AUTOSAR XML (schema 4.0)
package /Interfaces
  sender receiver interface If_Empty
package /Components
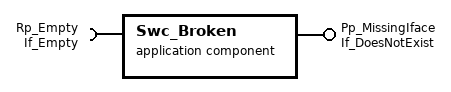
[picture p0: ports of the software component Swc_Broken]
  application sw component type Swc_Broken
    provide port Pp_MissingIface: provided-interface=If_DoesNotExist
    require port Rp_Empty: required-interface=If_Empty
